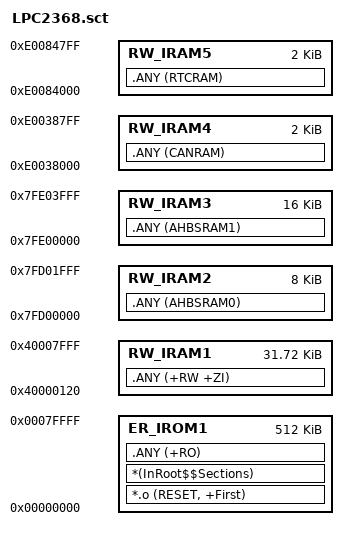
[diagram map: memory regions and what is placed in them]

LR_IROM1 0x00000000 0x80000  {    ; load region size_region
  ER_IROM1 0x00000000 0x80000  {  ; load address = execution address
   *.o (RESET, +First)
   *(InRoot$$Sections)
   .ANY (+RO)
  }
  RW_IRAM1 0x40000120 0x7EE0  {  ; RW data, inc space for realmonitor
   .ANY (+RW +ZI)
  }
  RW_IRAM2 0x7FD00000 0x2000  {  ; RW data, USB RAM
   .ANY (AHBSRAM0)
  }
  RW_IRAM3 0x7FE00000 0x4000  {  ; RW data, ETH RAM
   .ANY (AHBSRAM1)
  }
  RW_IRAM4 0xE0038000 0x0800  {  ; RW data, CAN RAM
   .ANY (CANRAM)
  }
  RW_IRAM5 0xE0084000 0x0800  {  ; RW data, RTC RAM
   .ANY (RTCRAM)
  }
}

